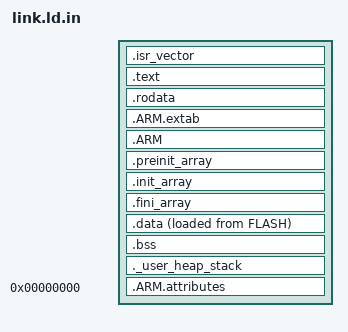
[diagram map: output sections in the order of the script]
_estack = ORIGIN(RAM) + LENGTH(RAM);
_Min_Heap_Size  = 0x2000;
_Min_Stack_Size = 0x1000;

SECTIONS
{
  .isr_vector : { KEEP(*(.isr_vector)) . = ALIGN(8); } >FLASH
  .text : { . = ALIGN(8); *(.text) *(.text*) *(.glue_7) *(.glue_7t)
            KEEP(*(.init)) KEEP(*(.fini)) . = ALIGN(8); _etext = .; } >FLASH
  .rodata : { . = ALIGN(8); *(.rodata) *(.rodata*) . = ALIGN(8); } >FLASH
  .ARM.extab : { *(.ARM.extab*) } >FLASH
  .ARM : { __exidx_start = .; *(.ARM.exidx*) __exidx_end = .; } >FLASH
  .preinit_array : { PROVIDE_HIDDEN(__preinit_array_start = .);
    KEEP(*(.preinit_array*)) PROVIDE_HIDDEN(__preinit_array_end = .); } >FLASH
  .init_array : { PROVIDE_HIDDEN(__init_array_start = .);
    KEEP(*(SORT(.init_array.*))) KEEP(*(.init_array*))
    PROVIDE_HIDDEN(__init_array_end = .); } >FLASH
  .fini_array : { PROVIDE_HIDDEN(__fini_array_start = .);
    KEEP(*(SORT(.fini_array.*))) KEEP(*(.fini_array*))
    PROVIDE_HIDDEN(__fini_array_end = .); } >FLASH

  _sidata = LOADADDR(.data);
  .data : { . = ALIGN(8); _sdata = .; *(.data) *(.data*) . = ALIGN(8);
            *(.RamFunc) *(.RamFunc*) . = ALIGN(8); _edata = .; } >RAM AT> FLASH
  .bss : { . = ALIGN(8); _sbss = .; __bss_start__ = _sbss;
           *(.bss) *(.bss*) *(COMMON) . = ALIGN(8); _ebss = .; __bss_end__ = _ebss; } >RAM
  ._user_heap_stack : { . = ALIGN(8); PROVIDE(end = .); PROVIDE(_end = .);
    . = . + _Min_Heap_Size; . = . + _Min_Stack_Size; . = ALIGN(8); } >RAM
  .ARM.attributes 0 : { *(.ARM.attributes) }
}
